AUTOSAR XML (schema 00044)
package /ComponentTypes
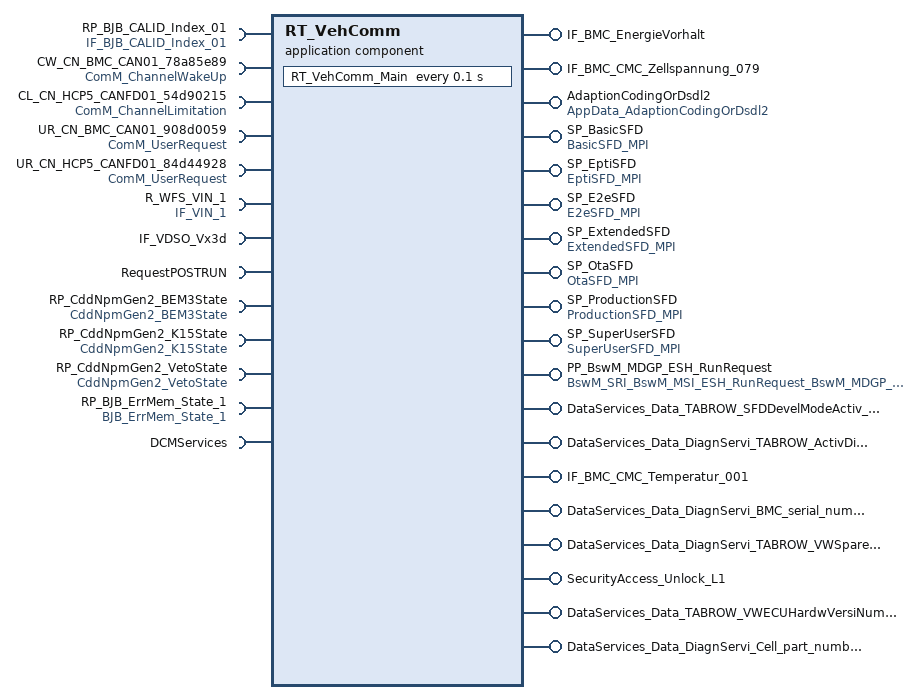
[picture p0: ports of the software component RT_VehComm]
  application sw component type RT_VehComm
    6 x require port:
      RP_BJB_CALID_Index_01: nonqueued-receiver-com-spec{data-element=DE_BJB_CALID_Index_01, filter=data-filter-type=ALWAYS, init-value=0}, required-interface=IF_BJB_CALID_Index_01
      CW_CN_BMC_CAN01_78a85e89: required-com-specs=[PreventWakeUp, GetInhibitionStatus], required-interface=ComM_ChannelWakeUp
      CL_CN_HCP5_CANFD01_54d90215: required-com-specs=[LimitChannelToNoComMode, GetInhibitionStatus], required-interface=ComM_ChannelLimitation
      UR_CN_BMC_CAN01_908d0059: required-com-specs=[RequestComMode, GetCurrentComMode, GetMaxComMode, GetRequestedComMode, GetCurrentPNCComMode], required-interface=ComM_UserRequest
      UR_CN_HCP5_CANFD01_84d44928: required-com-specs=[RequestComMode, GetCurrentComMode, GetMaxComMode, GetRequestedComMode, GetCurrentPNCComMode], required-interface=ComM_UserRequest
      R_WFS_VIN_1: nonqueued-receiver-com-spec{data-element=DE_VIN_1, filter=data-filter-type=ALWAYS, init-value=0}, required-interface=IF_VIN_1
    provide port IF_BMC_EnergieVorhalt: nonqueued-sender-com-spec{data-element=DE_BMC_EnergieVorhalt, init-value=0}, provided-interface=IF_BMC_EnergieVorhalt
    provide port IF_BMC_CMC_Zellspannung_079: nonqueued-sender-com-spec{data-element=DE_BMC_CMC_Zellspannung_079, init-value=0}, provided-interface=IF_BMC_CMC_Zellspannung_079
    require port IF_VDSO_Vx3d: nonqueued-receiver-com-spec{data-element=DE_VDSO_Vx3d, filter=data-filter-type=ALWAYS, init-value=0}, required-interface=IF_VDSO_Vx3d
    require port RequestPOSTRUN: nonqueued-receiver-com-spec{data-element=Request, filter=data-filter-type=ALWAYS, init-value=1}, required-interface=RequestPOSTRUN
    8 x provide port:
      AdaptionCodingOrDsdl2: server-com-spec{operation=Data, queue-length=1}, provided-interface=AppData_AdaptionCodingOrDsdl2
      SP_BasicSFD: mode-switch-sender-com-spec{mode-group=BasicSFDRole, queue-length=1}, provided-interface=BasicSFD_MPI
      SP_EptiSFD: mode-switch-sender-com-spec{mode-group=EptiSFDRole, queue-length=1}, provided-interface=EptiSFD_MPI
      SP_E2eSFD: mode-switch-sender-com-spec{mode-group=E2eSFDRole, queue-length=1}, provided-interface=E2eSFD_MPI
      SP_ExtendedSFD: mode-switch-sender-com-spec{mode-group=ExtendedSFDRole, queue-length=1}, provided-interface=ExtendedSFD_MPI
      SP_OtaSFD: mode-switch-sender-com-spec{mode-group=OtaSFDRole, queue-length=1}, provided-interface=OtaSFD_MPI
      SP_ProductionSFD: mode-switch-sender-com-spec{mode-group=ProductionSFDRole, queue-length=1}, provided-interface=ProductionSFD_MPI
      SP_SuperUserSFD: mode-switch-sender-com-spec{mode-group=SuperUserSFDRole, queue-length=1}, provided-interface=SuperUserSFD_MPI
    require port RP_CddNpmGen2_BEM3State: client-com-spec=SetBEM3State, required-interface=CddNpmGen2_BEM3State
    require port RP_CddNpmGen2_K15State: client-com-spec=SetK15State, required-interface=CddNpmGen2_K15State
    require port RP_CddNpmGen2_VetoState: client-com-spec=SetVetoState, required-interface=CddNpmGen2_VetoState
    provide port PP_BswM_MDGP_ESH_RunRequest: nonqueued-sender-com-spec=requestedMode, provided-interface=BswM_SRI_BswM_MSI_ESH_RunRequest_BswM_MDGP_ESH_RunRequest
    provide port DataServices_Data_TABROW_SFDDevelModeActiv_Read: provided-interface=DataServices_Data_TABROW_SFDDevelModeActiv_Read
      provided-com-specs:
        operation=ReadData, queue-length=1
        operation=ConditionCheckRead, queue-length=1
        operation=WriteData, queue-length=1
    require port RP_BJB_ErrMem_State_1: nonqueued-receiver-com-spec{data-element=BJB_ErrMem_State, init-value=2}, required-interface=BJB_ErrMem_State_1
    require port DCMServices: required-interface=DCMServices
      required-com-specs:
        GetSecurityLevel
        GetRequestKind
        SetActiveDiagnostic
        ResetToDefaultSession
        GetSesCtrlType
        GetActiveProtocol
    7 x provide port:
      DataServices_Data_DiagnServi_TABROW_ActivDiagnSessi_Read: provided-com-specs=[{operation=ReadData, queue-length=1}, {operation=ConditionCheckRead, queue-length=1}], provided-interface=DataServices_Data_DiagnServi_TABROW_ActivDiagnSessi_Read
      IF_BMC_CMC_Temperatur_001: nonqueued-sender-com-spec{data-element=DE_BMC_CMC_Temperatur_001, init-value=0}, provided-interface=IF_BMC_CMC_Temperatur_001
      DataServices_Data_DiagnServi_BMC_serial_number_Read: provided-interface=DataServices_Data_DiagnServi_BMC_serial_number_Read
        provided-com-specs:
          operation=ReadData, queue-length=1
          operation=ConditionCheckRead, queue-length=1
          operation=WriteData, queue-length=1
      DataServices_Data_DiagnServi_TABROW_VWSparePartNumbe_Read: provided-com-specs=[{operation=ReadData, queue-length=1}, {operation=ConditionCheckRead, queue-length=1}], provided-interface=DataServices_Data_DiagnServi_TABROW_VWSparePartNumbe_Read
      SecurityAccess_Unlock_L1: provided-com-specs=[{operation=CompareKey, queue-length=1}, {operation=GetSeed, queue-length=1}], provided-interface=SecurityAccess_Unlock_L1
      DataServices_Data_TABROW_VWECUHardwVersiNumbe_Read: provided-com-specs=[{operation=ReadData, queue-length=1}, {operation=ConditionCheckRead, queue-length=1}], provided-interface=DataServices_Data_TABROW_VWECUHardwVersiNumbe_Read
      DataServices_Data_DiagnServi_Cell_part_number_Read: provided-interface=DataServices_Data_DiagnServi_Cell_part_number_Read
        provided-com-specs:
          operation=ReadData, queue-length=1
          operation=ConditionCheckRead, queue-length=1
          operation=WriteData, queue-length=1
    behavior RT_VehComm_InternalBehavior: data-type-mapping=[defaultDataTypeMappingSet_CPFS, defaultDataTypeMappingSet_CPFS, RT_COM]
      timing event TMT_Runnable: start-on-event=RT_VehComm_Main, period=0.1
      init event Runnable_InitEvent: start-on-event=RT_VehComm_Init
      11 x operation invoked event:
        OIT_Runnable_AdaptionCodingOrDsdl2_Data: start-on-event=AppDataA_Runnable, operation=AdaptionCodingOrDsdl2.Data
        OIT_DataServices_Data_TABROW_SFDDevelModeActiv_Read_WriteData_DataServices_Data_TABROW_SFDDevelModeActiv_Read_WriteData: start-on-event=DataServices_Data_TABROW_SFDDevelModeActiv_Read_WriteData, operation=DataServices_Data_TABROW_SFDDevelModeActiv_Read.WriteData
        OIT_DataServices_Data_TABROW_SFDDevelModeActiv_Read_ConditionCheckRead_DataServices_Data_TABROW_SFDDevelModeActiv_Read_C3E62C407: start-on-event=DataServices_Data_TABROW_SFDDevelModeActiv_Read_ConditionCheckRead, operation=DataServices_Data_TABROW_SFDDevelModeActiv_Read.ConditionCheckRead
        OIT_DataServices_Data_TABROW_SFDDevelModeActiv_Read_ReadData_DataServices_Data_TABROW_SFDDevelModeActiv_Read_ReadData: start-on-event=DataServices_Data_TABROW_SFDDevelModeActiv_Read_ReadData, operation=DataServices_Data_TABROW_SFDDevelModeActiv_Read.ReadData
        OIT_DataServices_Data_DiagnServi_TABROW_ActivDiagnSessi_Read_ConditionCheckRead_DataServices_Data_DiagnServi_TABROW_Acti7F8046AA: start-on-event=DataServices_Data_DiagnServi_TABROW_ActivDiagnSessi_Read_ConditionCheckRead, operation=DataServices_Data_DiagnServi_TABROW_ActivDiagnSessi_Read.ConditionCheckRead
        OIT_DataServices_Data_DiagnServi_TABROW_ActivDiagnSessi_Read_ReadData_DataServices_Data_DiagnServi_TABROW_ActivDiagnSessB7F607CD: start-on-event=DataServices_Data_DiagnServi_TABROW_ActivDiagnSessi_Read_ReadData, operation=DataServices_Data_DiagnServi_TABROW_ActivDiagnSessi_Read.ReadData
        OIT_DataServices_Data_DiagnServi_BMC_serial_number_Read_WriteData_DataServices_Data_DiagnServi_BMC_serial_number_Read_WriteData: start-on-event=DataServices_Data_DiagnServi_BMC_serial_number_Read_WriteData, operation=DataServices_Data_DiagnServi_BMC_serial_number_Read.WriteData
        OIT_DataServices_Data_DiagnServi_BMC_serial_number_Read_ConditionCheckRead_DataServices_Data_DiagnServi_BMC_serial_numbe1156748E: start-on-event=DataServices_Data_DiagnServi_BMC_serial_number_Read_ConditionCheckRead, operation=DataServices_Data_DiagnServi_BMC_serial_number_Read.ConditionCheckRead
        OIT_DataServices_Data_DiagnServi_BMC_serial_number_Read_ReadData_DataServices_Data_DiagnServi_BMC_serial_number_Read_ReadData: start-on-event=DataServices_Data_DiagnServi_BMC_serial_number_Read_ReadData, operation=DataServices_Data_DiagnServi_BMC_serial_number_Read.ReadData
        OIT_DataServices_Data_DiagnServi_TABROW_VWSparePartNumbe_Read_ConditionCheckRead_DataServices_Data_DiagnServi_TABROW_VWS3BD33D71: start-on-event=DataServices_Data_DiagnServi_TABROW_VWSparePartNumbe_Read_ConditionCheckRead, operation=DataServices_Data_DiagnServi_TABROW_VWSparePartNumbe_Read.ConditionCheckRead
        OIT_DataServices_Data_DiagnServi_TABROW_VWSparePartNumbe_Read_ReadData_DataServices_Data_DiagnServi_TABROW_VWSparePartNuE8EAFA5F: start-on-event=DataServices_Data_DiagnServi_TABROW_VWSparePartNumbe_Read_ReadData, operation=DataServices_Data_DiagnServi_TABROW_VWSparePartNumbe_Read.ReadData
      13 x runnable:
        RT_VehComm_Main
          data-receive-point-by-arguments:
            4 x access:
              REC_RP_BJB_CALID_Index_01_DE_BJB_CALID_Index_01: accessed-variable=RP_BJB_CALID_Index_01.DE_BJB_CALID_Index_01
              REC_R_WFS_VIN_1_DE_VIN_1: accessed-variable=R_WFS_VIN_1.DE_VIN_1
              REC_IF_VDSO_Vx3d_DE_VDSO_Vx3d: accessed-variable=IF_VDSO_Vx3d.DE_VDSO_Vx3d
              REC_RP_BJB_ErrMem_State_1_BJB_ErrMem_State: accessed-variable=RP_BJB_ErrMem_State_1.BJB_ErrMem_State
          data-send-points:
            4 x access:
              SEND_IF_BMC_EnergieVorhalt_DE_BMC_EnergieVorhalt: accessed-variable=IF_BMC_EnergieVorhalt.DE_BMC_EnergieVorhalt
              SEND_IF_BMC_CMC_Zellspannung_079_DE_BMC_CMC_Zellspannung_079: accessed-variable=IF_BMC_CMC_Zellspannung_079.DE_BMC_CMC_Zellspannung_079
              SEND_PP_BswM_MDGP_ESH_RunRequest_requestedMode: accessed-variable=PP_BswM_MDGP_ESH_RunRequest.requestedMode
              SEND_IF_BMC_CMC_Temperatur_001_DE_BMC_CMC_Temperatur_001: accessed-variable=IF_BMC_CMC_Temperatur_001.DE_BMC_CMC_Temperatur_001
          7 x mode switch point:
            SWITCH_SP_BasicSFD_BasicSFDRole: mode-group=SP_BasicSFD.BasicSFDRole
            SWITCH_SP_EptiSFD_EptiSFDRole: mode-group=SP_EptiSFD.EptiSFDRole
            SWITCH_E2eSFD_MPI_E2eSFDRole: mode-group=SP_E2eSFD.E2eSFDRole
            SWITCH_ExtendedSFD_MPI_ExtendedSFDRole: mode-group=SP_ExtendedSFD.ExtendedSFDRole
            SWITCH_OtaSFD_MPI_OtaSFDRole: mode-group=SP_OtaSFD.OtaSFDRole
            SWITCH_SP_ProductionSFD_ProductionSFDRole: mode-group=SP_ProductionSFD.ProductionSFDRole
            SWITCH_SP_SuperUserSFD_SuperUserSFDRole: mode-group=SP_SuperUserSFD.SuperUserSFDRole
          4 x sync call:
            SC_RP_CddNpmGen2_BEM3State_SetBEM3State: operation=RP_CddNpmGen2_BEM3State.SetBEM3State
            SC_RP_CddNpmGen2_K15State_SetK15State: operation=RP_CddNpmGen2_K15State.SetK15State
            SC_RP_CddNpmGen2_VetoState_SetVetoState: operation=RP_CddNpmGen2_VetoState.SetVetoState
            SC_DCMServices_GetSesCtrlType: operation=DCMServices.GetSesCtrlType
        RT_VehComm_Init
          sync call SC_UR_CN_BMC_CAN01_908d0059_RequestComMode: operation=UR_CN_BMC_CAN01_908d0059.RequestComMode
          sync call SC_UR_CN_HCP5_CANFD01_84d44928_RequestComMode: operation=UR_CN_HCP5_CANFD01_84d44928.RequestComMode
        AppDataA_Runnable
        DataServices_Data_TABROW_SFDDevelModeActiv_Read_WriteData
        DataServices_Data_TABROW_SFDDevelModeActiv_Read_ConditionCheckRead
        DataServices_Data_TABROW_SFDDevelModeActiv_Read_ReadData
        DataServices_Data_DiagnServi_TABROW_ActivDiagnSessi_Read_ConditionCheckRead
        DataServices_Data_DiagnServi_TABROW_ActivDiagnSessi_Read_ReadData
        DataServices_Data_DiagnServi_BMC_serial_number_Read_WriteData
        DataServices_Data_DiagnServi_BMC_serial_number_Read_ConditionCheckRead
        DataServices_Data_DiagnServi_BMC_serial_number_Read_ReadData
        DataServices_Data_DiagnServi_TABROW_VWSparePartNumbe_Read_ConditionCheckRead
        DataServices_Data_DiagnServi_TABROW_VWSparePartNumbe_Read_ReadData
  swc implementation RT_VehComm_Implementation: behavior=RT_VehComm_InternalBehavior
